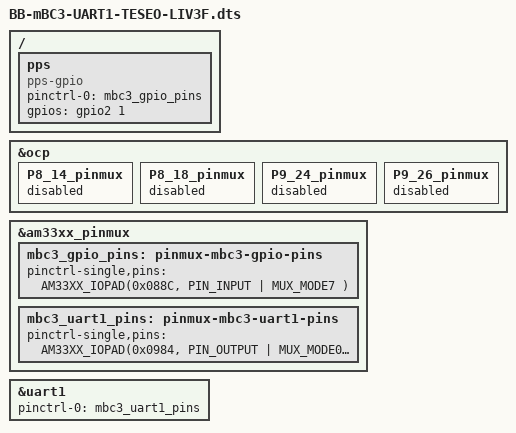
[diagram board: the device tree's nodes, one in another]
/*
 * Copyright (C) 2019 Robert Nelson <robertcnelson@gmail.com>
 *
 * This program is free software; you can redistribute it and/or modify
 * it under the terms of the GNU General Public License version 2 as
 * published by the Free Software Foundation.
 *
 * https://www.digikey.com/en/maker/projects/c4072044fba34f7b9d5210b973331940
 */

/dts-v1/;
/plugin/;

#include <dt-bindings/gpio/gpio.h>
#include <dt-bindings/pinctrl/am33xx.h>
#include <dt-bindings/interrupt-controller/irq.h>

/ {
	/*
	 * Free up the pins used by the cape from the pinmux helpers.
	 */
	fragment@0 {
		target = <&ocp>;
		__overlay__ {
			P8_14_pinmux { status = "disabled"; };	/* RESET - gpio0[26] */
			P8_18_pinmux { status = "disabled"; };	/* INT - gpio2[1] */

			P9_24_pinmux { status = "disabled"; };	/* RXD - spi0_sclk.uart2_rxd */
			P9_26_pinmux { status = "disabled"; };	/* TXD - spi0_d0.uart2_txd */
		};
	};

	fragment@1 {
		target = <&am33xx_pinmux>;
		__overlay__ {
			mbc3_gpio_pins: pinmux-mbc3-gpio-pins {
				pinctrl-single,pins = <
					AM33XX_IOPAD(0x088C, PIN_INPUT | MUX_MODE7 ) /* P8_18 (V12) gpmc_clk.gpio2[1] INT */
				>;
			};

			mbc3_uart1_pins: pinmux-mbc3-uart1-pins {
				pinctrl-single,pins = <
					AM33XX_IOPAD(0x0984, PIN_OUTPUT | MUX_MODE0) /* P9_24 (D15) uart1_txd.uart1_txd */
					AM33XX_IOPAD(0x0980, PIN_INPUT | MUX_MODE0 ) /* P9_26 (D16) uart1_rxd.uart1_rxd */
					AM33XX_IOPAD(0x0828, PIN_INPUT | MUX_MODE7 ) /* P8_14 (T11) gpmc_ad10.gpio0[26] RESET */
				>;
			};
		};
	};

	fragment@2 {
		target = <&uart1>;
		__overlay__ {
			status = "okay";
			pinctrl-names = "default";
			pinctrl-0 = <&mbc3_uart1_pins>;
		};
	};

	fragment@3 {
		target-path="/";
		__overlay__ {
			pps {
				status = "okay";
				compatible = "pps-gpio";
				pinctrl-names = "default";
				pinctrl-0 = <&mbc3_gpio_pins>;

				gpios = <&gpio2 1 GPIO_ACTIVE_HIGH>;
			};
		};
	};
};
